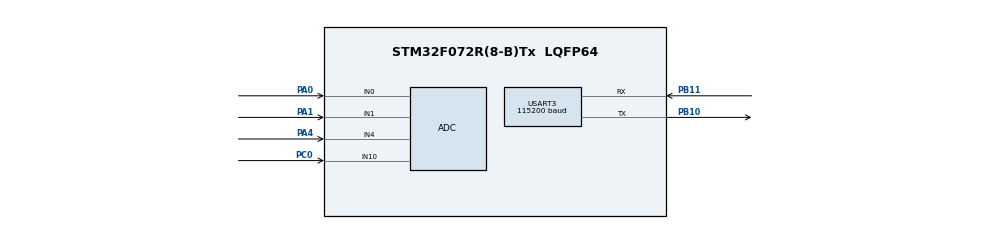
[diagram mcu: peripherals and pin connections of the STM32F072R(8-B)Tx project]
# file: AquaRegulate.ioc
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ADC.ClockPrescaler=ADC_CLOCK_SYNC_PCLK_DIV4
ADC.ContinuousConvMode=ENABLE
ADC.DMAContinuousRequests=ENABLE
ADC.Overrun=ADC_OVR_DATA_OVERWRITTEN
Dma.ADC.0.Direction=DMA_PERIPH_TO_MEMORY
Dma.ADC.0.Instance=DMA1_Channel1
Dma.ADC.0.MemDataAlignment=DMA_MDATAALIGN_HALFWORD
Dma.ADC.0.MemInc=DMA_MINC_ENABLE
Dma.ADC.0.Mode=DMA_CIRCULAR
Dma.ADC.0.PeriphDataAlignment=DMA_PDATAALIGN_HALFWORD
Dma.ADC.0.PeriphInc=DMA_PINC_DISABLE
Dma.ADC.0.Priority=DMA_PRIORITY_HIGH
Dma.Request0=ADC
Mcu.Family=STM32F0
Mcu.Name=STM32F072R(8-B)Tx
Mcu.Package=LQFP64
NVIC.DMA1_Channel1_IRQn=true\:0\:0\:false\:false\:true\:false\:true\:true
PA0.Mode=IN0
PA0.Signal=ADC_IN0
PA1.Mode=IN1
PA1.Signal=ADC_IN1
PA13.Mode=Serial_Wire
PA13.Signal=SYS_SWDIO
PA14.Mode=Serial_Wire
PA14.Signal=SYS_SWCLK
PA4.Mode=IN4
PA4.Signal=ADC_IN4
PB10.Mode=Asynchronous
PB10.Signal=USART3_TX
PB11.Mode=Asynchronous
PB11.Signal=USART3_RX
PC0.Mode=IN10
PC0.Signal=ADC_IN10
PF0-OSC_IN.Mode=HSE-External-Oscillator
PF0-OSC_IN.Signal=RCC_OSC_IN
PF1-OSC_OUT.Mode=HSE-External-Oscillator
PF1-OSC_OUT.Signal=RCC_OSC_OUT
ProjectManager.HeapSize=0x200
ProjectManager.StackSize=0x400
ProjectManager.TargetToolchain=MDK-ARM V5.32
USART3.BaudRate=115200
USART3.VirtualMode-Asynchronous=VM_ASYNC
board=custom

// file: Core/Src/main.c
/* USER CODE BEGIN Header */
/**
 ******************************************************************************
 * @file           : main.c
 * @brief          : Main program body
 ******************************************************************************
 * @attention
 *
 * Copyright (c) 2024 STMicroelectronics.
 * All rights reserved.
 *
 * This software is licensed under terms that can be found in the LICENSE file
 * in the root directory of this software component.
 * If no LICENSE file comes with this software, it is provided AS-IS.
 *
 ******************************************************************************
 */
/* USER CODE END Header */
#include "main.h"

ADC_HandleTypeDef hadc;
DMA_HandleTypeDef hdma_adc;

UART_HandleTypeDef huart3;

/* USER CODE BEGIN PV */

#include <string.h>
#include <stdio.h>

uint16_t adc_values[4]; // Array to store ADC values
char adc_str[100];      // String to store ADC values

void send_ADC_Using_UART(uint16_t adc_values[]);

/* USER CODE END PV */

void SystemClock_Config(void);
static void MX_GPIO_Init(void);
static void MX_DMA_Init(void);
static void MX_ADC_Init(void);
static void MX_USART3_UART_Init(void);

int main(void)
{

  /* MCU Configuration--------------------------------------------------------*/

  /* Reset of all peripherals, Initializes the Flash interface and the Systick. */
  HAL_Init();

  /* Configure the system clock */
  SystemClock_Config();

  /* Initialize all configured peripherals */
  MX_GPIO_Init();
  MX_DMA_Init();
  MX_ADC_Init();
  MX_USART3_UART_Init();
  /* USER CODE BEGIN 2 */

  HAL_UART_Transmit(&huart3, (uint8_t *)"ADC DMA started\r\n", 18, 1000);
  if (HAL_ADC_Start_DMA(&hadc, (uint32_t *)adc_values, 4) != HAL_OK)
  {
    HAL_UART_Transmit(&huart3, (uint8_t *)"ADC DMA failed\r\n", 17, 1000);
    Error_Handler();
  }
  else
  {
    HAL_UART_Transmit(&huart3, (uint8_t *)"ADC DMA started 1\r\n", 19, 1000);
  }

  // HAL_UART_Transmit(&huart3, (uint8_t *)"ADC DMA started 2\r\n", 20, 1000);

  /* USER CODE END 2 */

  /* Infinite loop */
  while (1)
  {

    /* USER CODE BEGIN 3 */

    // sprintf(adc_str, "%d", adc_values[0]);
    // HAL_UART_Transmit(&huart3, (uint8_t *)"ADC Value 1: ", 13, HAL_MAX_DELAY);
    // HAL_UART_Transmit(&huart3, (uint8_t *)adc_str, strlen(adc_str), HAL_MAX_DELAY);
    // HAL_UART_Transmit(&huart3, (uint8_t *)"\r\n", 2, HAL_MAX_DELAY);

    // // Convert adc_value for channel 11 to string and send over UART or display
    // sprintf(adc_str, "%d", adc_values[1]);
    // HAL_UART_Transmit(&huart3, (uint8_t *)"ADC Value 2: ", 13, HAL_MAX_DELAY);
    // HAL_UART_Transmit(&huart3, (uint8_t *)adc_str, strlen(adc_str), HAL_MAX_DELAY);
    // HAL_UART_Transmit(&huart3, (uint8_t *)"\r\n", 2, HAL_MAX_DELAY);

    // sprintf(adc_str, "%d", adc_values[2]);
    // HAL_UART_Transmit(&huart3, (uint8_t *)"ADC Value 3: ", 13, HAL_MAX_DELAY);
    // HAL_UART_Transmit(&huart3, (uint8_t *)adc_str, strlen(adc_str), HAL_MAX_DELAY);
    // HAL_UART_Transmit(&huart3, (uint8_t *)"\r\n", 2, HAL_MAX_DELAY);

    // sprintf(adc_str, "%d", adc_values[3]);
    // HAL_UART_Transmit(&huart3, (uint8_t *)"ADC Value 4: ", 13, HAL_MAX_DELAY);
    // HAL_UART_Transmit(&huart3, (uint8_t *)adc_str, strlen(adc_str), HAL_MAX_DELAY);
    // HAL_UART_Transmit(&huart3, (uint8_t *)"\r\n", 2, HAL_MAX_DELAY);

    // HAL_UART_Transmit(&huart3, (uint8_t *)"\r\n", 2, HAL_MAX_DELAY);

    // HAL_Delay(1000); // Delay for 1 second
    send_ADC_Using_UART(adc_values);
  }
  /* USER CODE END 3 */
}

void send_ADC_Using_UART(uint16_t adc_values[])
{
  // Format the ADC values to string
  sprintf(adc_str, "{1: %d, 2: %d, 3: %d, 4: %d}\r\n",
          adc_values[0], adc_values[1], adc_values[2], adc_values[3]);

  // Send the formatted ADC values over UART
  HAL_UART_Transmit(&huart3, (uint8_t *)adc_str, strlen(adc_str), HAL_MAX_DELAY);

  // Transmit a new line character
  HAL_UART_Transmit(&huart3, (uint8_t *)"\r\n", 2, HAL_MAX_DELAY);

  // Delay for 1 second
  HAL_Delay(1000);
}
void SystemClock_Config(void)
{
  RCC_OscInitTypeDef RCC_OscInitStruct = {0};
  RCC_ClkInitTypeDef RCC_ClkInitStruct = {0};

  /** Initializes the RCC Oscillators according to the specified parameters
   * in the RCC_OscInitTypeDef structure.
   */
  RCC_OscInitStruct.OscillatorType = RCC_OSCILLATORTYPE_HSI;
  RCC_OscInitStruct.HSIState = RCC_HSI_ON;
  RCC_OscInitStruct.HSICalibrationValue = RCC_HSICALIBRATION_DEFAULT;
  RCC_OscInitStruct.PLL.PLLState = RCC_PLL_NONE;
  if (HAL_RCC_OscConfig(&RCC_OscInitStruct) != HAL_OK)
  {
    Error_Handler();
  }

  /** Initializes the CPU, AHB and APB buses clocks
   */
  RCC_ClkInitStruct.ClockType = RCC_CLOCKTYPE_HCLK | RCC_CLOCKTYPE_SYSCLK | RCC_CLOCKTYPE_PCLK1;
  RCC_ClkInitStruct.SYSCLKSource = RCC_SYSCLKSOURCE_HSI;
  RCC_ClkInitStruct.AHBCLKDivider = RCC_SYSCLK_DIV1;
  RCC_ClkInitStruct.APB1CLKDivider = RCC_HCLK_DIV1;

  if (HAL_RCC_ClockConfig(&RCC_ClkInitStruct, FLASH_LATENCY_0) != HAL_OK)
  {
    Error_Handler();
  }
}

static void MX_ADC_Init(void)
{

  ADC_ChannelConfTypeDef sConfig = {0};

  /** Configure the global features of the ADC (Clock, Resolution, Data Alignment and number of conversion)
   */
  hadc.Instance = ADC1;
  hadc.Init.ClockPrescaler = ADC_CLOCK_SYNC_PCLK_DIV4;
  hadc.Init.Resolution = ADC_RESOLUTION_12B;
  hadc.Init.DataAlign = ADC_DATAALIGN_RIGHT;
  hadc.Init.ScanConvMode = ADC_SCAN_DIRECTION_FORWARD;
  hadc.Init.EOCSelection = ADC_EOC_SINGLE_CONV;
  hadc.Init.LowPowerAutoWait = DISABLE;
  hadc.Init.LowPowerAutoPowerOff = DISABLE;
  hadc.Init.ContinuousConvMode = ENABLE;
  hadc.Init.DiscontinuousConvMode = DISABLE;
  hadc.Init.ExternalTrigConv = ADC_SOFTWARE_START;
  hadc.Init.ExternalTrigConvEdge = ADC_EXTERNALTRIGCONVEDGE_NONE;
  hadc.Init.DMAContinuousRequests = ENABLE;
  hadc.Init.Overrun = ADC_OVR_DATA_OVERWRITTEN;
  if (HAL_ADC_Init(&hadc) != HAL_OK)
  {
    Error_Handler();
  }

  /** Configure for the selected ADC regular channel to be converted.
   */
  sConfig.Channel = ADC_CHANNEL_0;
  sConfig.Rank = ADC_RANK_CHANNEL_NUMBER;
  sConfig.SamplingTime = ADC_SAMPLETIME_1CYCLE_5;
  if (HAL_ADC_ConfigChannel(&hadc, &sConfig) != HAL_OK)
  {
    Error_Handler();
  }

  /** Configure for the selected ADC regular channel to be converted.
   */
  sConfig.Channel = ADC_CHANNEL_1;
  if (HAL_ADC_ConfigChannel(&hadc, &sConfig) != HAL_OK)
  {
    Error_Handler();
  }

  /** Configure for the selected ADC regular channel to be converted.
   */
  sConfig.Channel = ADC_CHANNEL_4;
  if (HAL_ADC_ConfigChannel(&hadc, &sConfig) != HAL_OK)
  {
    Error_Handler();
  }

  /** Configure for the selected ADC regular channel to be converted.
   */
  sConfig.Channel = ADC_CHANNEL_10;
  if (HAL_ADC_ConfigChannel(&hadc, &sConfig) != HAL_OK)
  {
    Error_Handler();
  }
}

static void MX_USART3_UART_Init(void)
{

  huart3.Instance = USART3;
  huart3.Init.BaudRate = 115200;
  huart3.Init.WordLength = UART_WORDLENGTH_8B;
  huart3.Init.StopBits = UART_STOPBITS_1;
  huart3.Init.Parity = UART_PARITY_NONE;
  huart3.Init.Mode = UART_MODE_TX_RX;
  huart3.Init.HwFlowCtl = UART_HWCONTROL_NONE;
  huart3.Init.OverSampling = UART_OVERSAMPLING_16;
  huart3.Init.OneBitSampling = UART_ONE_BIT_SAMPLE_DISABLE;
  huart3.AdvancedInit.AdvFeatureInit = UART_ADVFEATURE_NO_INIT;
  if (HAL_UART_Init(&huart3) != HAL_OK)
  {
    Error_Handler();
  }
}

static void MX_DMA_Init(void)
{

  /* DMA controller clock enable */
  __HAL_RCC_DMA1_CLK_ENABLE();

  /* DMA interrupt init */
  /* DMA1_Channel1_IRQn interrupt configuration */
  // HAL_NVIC_SetPriority(DMA1_Channel1_IRQn, 0, 0);
  // HAL_NVIC_EnableIRQ(DMA1_Channel1_IRQn);
}

static void MX_GPIO_Init(void)
{

  /* GPIO Ports Clock Enable */
  __HAL_RCC_GPIOF_CLK_ENABLE();
  __HAL_RCC_GPIOC_CLK_ENABLE();
  __HAL_RCC_GPIOA_CLK_ENABLE();
  __HAL_RCC_GPIOB_CLK_ENABLE();

}

void Error_Handler(void)
{
  __disable_irq();
  while (1)
  {
  }
}
